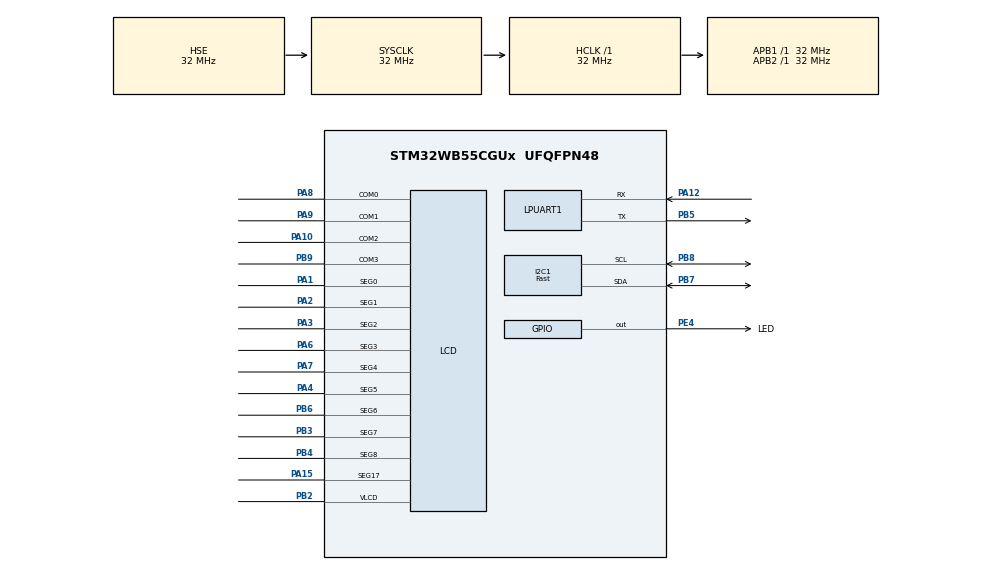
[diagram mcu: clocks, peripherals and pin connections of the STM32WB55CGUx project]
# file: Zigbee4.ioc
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Dma.LPUART1_RX.1.Direction=DMA_PERIPH_TO_MEMORY
Dma.LPUART1_RX.1.EventEnable=DISABLE
Dma.LPUART1_RX.1.Instance=DMA1_Channel2
Dma.LPUART1_RX.1.MemDataAlignment=DMA_MDATAALIGN_BYTE
Dma.LPUART1_RX.1.MemInc=DMA_MINC_ENABLE
Dma.LPUART1_RX.1.Mode=DMA_NORMAL
Dma.LPUART1_RX.1.PeriphDataAlignment=DMA_PDATAALIGN_BYTE
Dma.LPUART1_RX.1.PeriphInc=DMA_PINC_DISABLE
Dma.LPUART1_RX.1.Polarity=HAL_DMAMUX_REQ_GEN_RISING
Dma.LPUART1_RX.1.Priority=DMA_PRIORITY_LOW
Dma.LPUART1_RX.1.RequestNumber=1
Dma.LPUART1_RX.1.SignalID=NONE
Dma.LPUART1_RX.1.SyncEnable=DISABLE
Dma.LPUART1_RX.1.SyncPolarity=HAL_DMAMUX_SYNC_NO_EVENT
Dma.LPUART1_RX.1.SyncRequestNumber=1
Dma.LPUART1_RX.1.SyncSignalID=NONE
Dma.LPUART1_TX.0.Direction=DMA_MEMORY_TO_PERIPH
Dma.LPUART1_TX.0.EventEnable=DISABLE
Dma.LPUART1_TX.0.Instance=DMA1_Channel1
Dma.LPUART1_TX.0.MemDataAlignment=DMA_MDATAALIGN_BYTE
Dma.LPUART1_TX.0.MemInc=DMA_MINC_ENABLE
Dma.LPUART1_TX.0.Mode=DMA_NORMAL
Dma.LPUART1_TX.0.PeriphDataAlignment=DMA_PDATAALIGN_BYTE
Dma.LPUART1_TX.0.PeriphInc=DMA_PINC_DISABLE
Dma.LPUART1_TX.0.Polarity=HAL_DMAMUX_REQ_GEN_RISING
Dma.LPUART1_TX.0.Priority=DMA_PRIORITY_LOW
Dma.LPUART1_TX.0.RequestNumber=1
Dma.LPUART1_TX.0.SignalID=NONE
Dma.LPUART1_TX.0.SyncEnable=DISABLE
Dma.LPUART1_TX.0.SyncPolarity=HAL_DMAMUX_SYNC_NO_EVENT
Dma.LPUART1_TX.0.SyncRequestNumber=1
Dma.LPUART1_TX.0.SyncSignalID=NONE
Dma.Request0=LPUART1_TX
Dma.Request1=LPUART1_RX
I2C1.DualAddressMode=I2C_DUALADDRESS_ENABLE
I2C1.I2C_Speed_Mode=I2C_Fast
I2C1.Timing=0x0060112F
LCD.Bias=LCD_BIAS_1_3
LCD.BlinkFrequency=LCD_BLINKFREQUENCY_DIV8
LCD.BlinkMode=LCD_BLINKMODE_OFF
LCD.Contrast=LCD_CONTRASTLEVEL_3
LCD.HighDrive=LCD_HIGHDRIVE_ENABLE
Mcu.Family=STM32WB
Mcu.Name=STM32WB55CGUx
Mcu.Package=UFQFPN48
Mcu.UserConstants=TEMP_MIN_2,-4000;TEMP_MAX_2,14500;TEMP_TOLERANCE_2,10
NVIC.C2SEV_PWR_C2H_IRQn=true\:0\:0\:false\:false\:true\:true\:false\:true
NVIC.DMA1_Channel1_IRQn=true\:0\:0\:false\:false\:true\:false\:true\:true
NVIC.DMA1_Channel2_IRQn=true\:0\:0\:false\:false\:true\:false\:true\:true
NVIC.FLASH_IRQn=true\:0\:0\:false\:false\:true\:true\:true\:true
NVIC.FPU_IRQn=true\:0\:0\:false\:false\:true\:true\:false\:true
NVIC.HSEM_IRQn=true\:0\:0\:false\:false\:true\:false\:true\:true
NVIC.I2C1_EV_IRQn=true\:0\:0\:false\:false\:true\:true\:true\:true
NVIC.IPCC_C1_RX_IRQn=true\:0\:0\:false\:false\:true\:true\:true\:true
NVIC.IPCC_C1_TX_IRQn=true\:0\:0\:false\:false\:true\:true\:true\:true
NVIC.PVD_PVM_IRQn=true\:0\:0\:false\:false\:true\:true\:true\:true
NVIC.PWR_SOTF_BLEACT_802ACT_RFPHASE_IRQn=true\:0\:0\:false\:false\:true\:true\:false\:true
NVIC.PriorityGroup=NVIC_PRIORITYGROUP_4
NVIC.RTC_WKUP_IRQn=true\:0\:0\:false\:false\:true\:true\:true\:true
NVIC.TIM1_UP_TIM16_IRQn=true\:0\:0\:false\:false\:true\:true\:true\:true
OSC_IN.Mode=HSE-External-Oscillator
OSC_IN.Signal=RCC_OSC_IN
OSC_OUT.Mode=HSE-External-Oscillator
OSC_OUT.Signal=RCC_OSC_OUT
PA1.Mode=SEG0
PA1.Signal=LCD_SEG0
PA10.Mode=1/4 Duty Cycle
PA10.Signal=LCD_COM2
PA12.Mode=Asynchronous
PA12.Signal=LPUART1_RX
PA13.Mode=Serial_Wire
PA13.Signal=SYS_JTMS-SWDIO
PA14.Mode=Serial_Wire
PA14.Signal=SYS_JTCK-SWCLK
PA15.Mode=SEG17
PA15.Signal=LCD_SEG17
PA2.Mode=SEG1
PA2.Signal=LCD_SEG1
PA3.Mode=SEG2
PA3.Signal=LCD_SEG2
PA4.Mode=SEG5
PA4.Signal=LCD_SEG5
PA6.Mode=SEG3
PA6.Signal=LCD_SEG3
PA7.Mode=SEG4
PA7.Signal=LCD_SEG4
PA8.Mode=1/4 Duty Cycle
PA8.Signal=LCD_COM0
PA9.Mode=1/4 Duty Cycle
PA9.Signal=LCD_COM1
PB2.Mode=1/4 Duty Cycle
PB2.Signal=LCD_VLCD
PB3.Mode=SEG7
PB3.Signal=LCD_SEG7
PB4.Mode=SEG8
PB4.Signal=LCD_SEG8
PB5.Mode=Asynchronous
PB5.Signal=LPUART1_TX
PB6.Mode=SEG6
PB6.Signal=LCD_SEG6
PB7.Mode=I2C
PB7.Signal=I2C1_SDA
PB8.Mode=I2C
PB8.Signal=I2C1_SCL
PB9.Mode=1/4 Duty Cycle
PB9.Signal=LCD_COM3
PC14-OSC32_IN.Mode=LSE-External-Oscillator
PC14-OSC32_IN.Signal=RCC_OSC32_IN
PC15-OSC32_OUT.Mode=LSE-External-Oscillator
PC15-OSC32_OUT.Signal=RCC_OSC32_OUT
PE4.GPIO_Label=LED
PE4.Signal=GPIO_Output
ProjectManager.HeapSize=0x19000
ProjectManager.StackSize=0x1000
ProjectManager.TargetToolchain=CMake
RCC.AHBFreq_Value=32000000
RCC.APB1Freq_Value=32000000
RCC.APB1TimFreq_Value=32000000
RCC.APB2Freq_Value=32000000
RCC.APB2TimFreq_Value=32000000
RCC.APB3Freq_Value=16000000
RCC.CortexFreq_Value=32000000
RCC.HCLKFreq_Value=32000000
RCC.HSE_VALUE=32000000
RCC.HSI48_VALUE=48000000
RCC.HSI_VALUE=16000000
RCC.RTCClockSelection=RCC_RTCCLKSOURCE_LSE
RCC.SMPSCLockSelection=RCC_SMPSCLKSOURCE_HSE
RCC.SYSCLKFreq_VALUE=32000000
RCC.SYSCLKSource=RCC_SYSCLKSOURCE_HSE
RCC.VCOOutputFreq_Value=32000000
RF1.Mode=RF1_Activate
RF1.Signal=RF_RF1
STM32_WPAN.APPLI_CONFIG_LOG_LEVEL=LOG_LEVEL_DEBG
STM32_WPAN.CFG_CLI_UART=hw_lpuart1
STM32_WPAN.CFG_DEBUG_TRACE_FULL=1
STM32_WPAN.CFG_DEBUG_TRACE_LIGHT=1
STM32_WPAN.CFG_DEBUG_TRACE_UART=hw_uart1
STM32_WPAN.CFG_HW_LPUART1_ENABLED=1
STM32_WPAN.CFG_HW_USART1_ENABLED=1
STM32_WPAN.CFG_LSCLK_LSE=0
STM32_WPAN.CFG_USE_SMPS=1
STM32_WPAN.ENDPOINT1_DEVICE_ID=ZCL_DEVICE_METER_INTERFACE
STM32_WPAN.ENDPOINT1_ID_ZGB=10
STM32_WPAN.ENDPOINT2_DEVICE_ID=ZCL_DEVICE_METER_INTERFACE
STM32_WPAN.ENDPOINT2_ID_ZGB=11
STM32_WPAN.ZCL_BASIC_ENDPOINT1=CLIENT_SERVER
STM32_WPAN.ZCL_BASIC_ENDPOINT2=CLIENT_SERVER
STM32_WPAN.ZCL_IDENTIFY_ENDPOINT1=NONE
STM32_WPAN.ZCL_TEMPERATURE_MEASUREMENT_ENDPOINT2=CLIENT_SERVER
STM32_WPAN.ZCL_WATER_CONTENT_MEASUREMENT_ENDPOINT1=CLIENT_SERVER
STM32_WPAN.ZGB_CHANNEL=13
STM32_WPAN.ZGB_DEVICE_ROLE=ROUTER
STM32_WPAN.ZGB_ENDPOINT1_PROFILE_ID=ZCL_PROFILE_HOME_AUTOMATION
STM32_WPAN.ZGB_NB_ENDPOINTS=3
STM32_WPAN.ZGB_NW_MODE=CENTRALIZED
TIM1.Period=50000
TIM1.Prescaler=720
VP_HSEM_VS_HSEM.Mode=HSEM_Activate
VP_IPCC_VS_IPCC.Mode=IPCC_Activate
VP_MEMORYMAP_VS_MEMORYMAP.Mode=CurAppReg
VP_RTC_VS_RTC_Activate.Mode=RTC_Enabled
VP_RTC_VS_RTC_WakeUp_intern.Mode=WakeUp
VP_SEQUENCER_VS_SEQUENCER.Mode=SEQUENCER_Enabled
VP_STM32_WPAN_VS_ZIGBEE.Mode=MOD_ZGB_ENDPOINT
VP_TIM1_VS_ClockSourceINT.Mode=Internal
VP_TINY_LPM_VS_TINY_LPM.Mode=TINY_LPM_Enabled
board=custom

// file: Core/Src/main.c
/* USER CODE BEGIN Header */
/**
  ******************************************************************************
  * @file           : main.c
  * @brief          : Main program body
  ******************************************************************************
  * @attention
  *
  * Copyright (c) 2025 STMicroelectronics.
  * All rights reserved.
  *
  * This software is licensed under terms that can be found in the LICENSE file
  * in the root directory of this software component.
  * If no LICENSE file comes with this software, it is provided AS-IS.
  *
  ******************************************************************************
  */
/* USER CODE END Header */
#include "main.h"

I2C_HandleTypeDef hi2c1;

IPCC_HandleTypeDef hipcc;

LCD_HandleTypeDef hlcd;

UART_HandleTypeDef hlpuart1;
DMA_HandleTypeDef hdma_lpuart1_tx;
DMA_HandleTypeDef hdma_lpuart1_rx;

RTC_HandleTypeDef hrtc;

TIM_HandleTypeDef htim1;

void SystemClock_Config(void);
void PeriphCommonClock_Config(void);
static void MX_GPIO_Init(void);
static void MX_DMA_Init(void);
static void MX_LPUART1_UART_Init(void);
static void MX_IPCC_Init(void);
static void MX_RTC_Init(void);
static void MX_I2C1_Init(void);
static void MX_TIM1_Init(void);
static void MX_LCD_Init(void);
static void MX_RF_Init(void);
/* USER CODE BEGIN PFP */

extern void TimerCallBack();

/* USER CODE END PFP */

/* USER CODE BEGIN 0 */
void HAL_TIM_PeriodElapsedCallback(TIM_HandleTypeDef *htim)
{
        if(htim->Instance == TIM1) //check if the interrupt comes from TIM1
        {
          TimerCallBack();
        }
}
/* USER CODE END 0 */

int main(void)
{

  /* MCU Configuration--------------------------------------------------------*/

  /* Reset of all peripherals, Initializes the Flash interface and the Systick. */
  HAL_Init();
  /* Config code for STM32_WPAN (HSE Tuning must be done before system clock configuration) */
  MX_APPE_Config();

  /* Configure the system clock */
  SystemClock_Config();

  /* Configure the peripherals common clocks */
  PeriphCommonClock_Config();

  /* IPCC initialisation */
  MX_IPCC_Init();

  /* Initialize all configured peripherals */
  MX_GPIO_Init();
  MX_DMA_Init();
  MX_LPUART1_UART_Init();
  MX_RTC_Init();
  MX_I2C1_Init();
  MX_TIM1_Init();
  MX_LCD_Init();
  MX_RF_Init();
  /* USER CODE BEGIN 2 */
  HAL_TIM_Base_Start_IT(&htim1);

  /* USER CODE END 2 */

  /* Init code for STM32_WPAN */
  MX_APPE_Init();

  /* Infinite loop */
  while (1)
  {
    MX_APPE_Process();

  }
}

void SystemClock_Config(void)
{
  RCC_OscInitTypeDef RCC_OscInitStruct = {0};
  RCC_ClkInitTypeDef RCC_ClkInitStruct = {0};

  /** Configure LSE Drive Capability
  */
  HAL_PWR_EnableBkUpAccess();
  __HAL_RCC_LSEDRIVE_CONFIG(RCC_LSEDRIVE_MEDIUMHIGH);

  /** Configure the main internal regulator output voltage
  */
  __HAL_PWR_VOLTAGESCALING_CONFIG(PWR_REGULATOR_VOLTAGE_SCALE1);

  /** Initializes the RCC Oscillators according to the specified parameters
  * in the RCC_OscInitTypeDef structure.
  */
  RCC_OscInitStruct.OscillatorType = RCC_OSCILLATORTYPE_HSI|RCC_OSCILLATORTYPE_HSE
                              |RCC_OSCILLATORTYPE_LSE;
  RCC_OscInitStruct.HSEState = RCC_HSE_ON;
  RCC_OscInitStruct.LSEState = RCC_LSE_ON;
  RCC_OscInitStruct.HSIState = RCC_HSI_ON;
  RCC_OscInitStruct.HSICalibrationValue = RCC_HSICALIBRATION_DEFAULT;
  RCC_OscInitStruct.PLL.PLLState = RCC_PLL_NONE;
  if (HAL_RCC_OscConfig(&RCC_OscInitStruct) != HAL_OK)
  {
    Error_Handler();
  }

  /** Configure the SYSCLKSource, HCLK, PCLK1 and PCLK2 clocks dividers
  */
  RCC_ClkInitStruct.ClockType = RCC_CLOCKTYPE_HCLK4|RCC_CLOCKTYPE_HCLK2
                              |RCC_CLOCKTYPE_HCLK|RCC_CLOCKTYPE_SYSCLK
                              |RCC_CLOCKTYPE_PCLK1|RCC_CLOCKTYPE_PCLK2;
  RCC_ClkInitStruct.SYSCLKSource = RCC_SYSCLKSOURCE_HSE;
  RCC_ClkInitStruct.AHBCLKDivider = RCC_SYSCLK_DIV1;
  RCC_ClkInitStruct.APB1CLKDivider = RCC_HCLK_DIV1;
  RCC_ClkInitStruct.APB2CLKDivider = RCC_HCLK_DIV1;
  RCC_ClkInitStruct.AHBCLK2Divider = RCC_SYSCLK_DIV1;
  RCC_ClkInitStruct.AHBCLK4Divider = RCC_SYSCLK_DIV1;

  if (HAL_RCC_ClockConfig(&RCC_ClkInitStruct, FLASH_LATENCY_1) != HAL_OK)
  {
    Error_Handler();
  }
}

void PeriphCommonClock_Config(void)
{
  RCC_PeriphCLKInitTypeDef PeriphClkInitStruct = {0};

  /** Initializes the peripherals clock
  */
  PeriphClkInitStruct.PeriphClockSelection = RCC_PERIPHCLK_SMPS|RCC_PERIPHCLK_RFWAKEUP;
  PeriphClkInitStruct.RFWakeUpClockSelection = RCC_RFWKPCLKSOURCE_HSE_DIV1024;
  PeriphClkInitStruct.SmpsClockSelection = RCC_SMPSCLKSOURCE_HSE;
  PeriphClkInitStruct.SmpsDivSelection = RCC_SMPSCLKDIV_RANGE0;

  if (HAL_RCCEx_PeriphCLKConfig(&PeriphClkInitStruct) != HAL_OK)
  {
    Error_Handler();
  }
}

static void MX_I2C1_Init(void)
{

  hi2c1.Instance = I2C1;
  hi2c1.Init.Timing = 0x0060112F;
  hi2c1.Init.OwnAddress1 = 0;
  hi2c1.Init.AddressingMode = I2C_ADDRESSINGMODE_7BIT;
  hi2c1.Init.DualAddressMode = I2C_DUALADDRESS_ENABLE;
  hi2c1.Init.OwnAddress2 = 0;
  hi2c1.Init.OwnAddress2Masks = I2C_OA2_NOMASK;
  hi2c1.Init.GeneralCallMode = I2C_GENERALCALL_DISABLE;
  hi2c1.Init.NoStretchMode = I2C_NOSTRETCH_DISABLE;
  if (HAL_I2C_Init(&hi2c1) != HAL_OK)
  {
    Error_Handler();
  }

  /** Configure Analogue filter
  */
  if (HAL_I2CEx_ConfigAnalogFilter(&hi2c1, I2C_ANALOGFILTER_ENABLE) != HAL_OK)
  {
    Error_Handler();
  }

  /** Configure Digital filter
  */
  if (HAL_I2CEx_ConfigDigitalFilter(&hi2c1, 0) != HAL_OK)
  {
    Error_Handler();
  }

}

static void MX_IPCC_Init(void)
{

  hipcc.Instance = IPCC;
  if (HAL_IPCC_Init(&hipcc) != HAL_OK)
  {
    Error_Handler();
  }

}

static void MX_LCD_Init(void)
{

  hlcd.Instance = LCD;
  hlcd.Init.Prescaler = LCD_PRESCALER_1;
  hlcd.Init.Divider = LCD_DIVIDER_16;
  hlcd.Init.Duty = LCD_DUTY_1_4;
  hlcd.Init.Bias = LCD_BIAS_1_3;
  hlcd.Init.VoltageSource = LCD_VOLTAGESOURCE_INTERNAL;
  hlcd.Init.Contrast = LCD_CONTRASTLEVEL_3;
  hlcd.Init.DeadTime = LCD_DEADTIME_0;
  hlcd.Init.PulseOnDuration = LCD_PULSEONDURATION_1;
  hlcd.Init.MuxSegment = LCD_MUXSEGMENT_DISABLE;
  hlcd.Init.BlinkMode = LCD_BLINKMODE_OFF;
  hlcd.Init.BlinkFrequency = LCD_BLINKFREQUENCY_DIV8;
  hlcd.Init.HighDrive = LCD_HIGHDRIVE_ENABLE;
  if (HAL_LCD_Init(&hlcd) != HAL_OK)
  {
    Error_Handler();
  }

  /** Enable the High Driver
  */
  __HAL_LCD_HIGHDRIVER_ENABLE(&hlcd);

}

static void MX_LPUART1_UART_Init(void)
{

  hlpuart1.Instance = LPUART1;
  hlpuart1.Init.BaudRate = 115200;
  hlpuart1.Init.WordLength = UART_WORDLENGTH_8B;
  hlpuart1.Init.StopBits = UART_STOPBITS_1;
  hlpuart1.Init.Parity = UART_PARITY_NONE;
  hlpuart1.Init.Mode = UART_MODE_TX_RX;
  hlpuart1.Init.HwFlowCtl = UART_HWCONTROL_NONE;
  hlpuart1.Init.OneBitSampling = UART_ONE_BIT_SAMPLE_DISABLE;
  hlpuart1.Init.ClockPrescaler = UART_PRESCALER_DIV1;
  hlpuart1.AdvancedInit.AdvFeatureInit = UART_ADVFEATURE_NO_INIT;
  hlpuart1.FifoMode = UART_FIFOMODE_DISABLE;
  if (HAL_UART_Init(&hlpuart1) != HAL_OK)
  {
    Error_Handler();
  }
  if (HAL_UARTEx_SetTxFifoThreshold(&hlpuart1, UART_TXFIFO_THRESHOLD_1_8) != HAL_OK)
  {
    Error_Handler();
  }
  if (HAL_UARTEx_SetRxFifoThreshold(&hlpuart1, UART_RXFIFO_THRESHOLD_1_8) != HAL_OK)
  {
    Error_Handler();
  }
  if (HAL_UARTEx_DisableFifoMode(&hlpuart1) != HAL_OK)
  {
    Error_Handler();
  }

}

static void MX_RF_Init(void)
{

}

static void MX_RTC_Init(void)
{

  /** Initialize RTC Only
  */
  hrtc.Instance = RTC;
  hrtc.Init.HourFormat = RTC_HOURFORMAT_24;
  hrtc.Init.AsynchPrediv = CFG_RTC_ASYNCH_PRESCALER;
  hrtc.Init.SynchPrediv = CFG_RTC_SYNCH_PRESCALER;
  hrtc.Init.OutPut = RTC_OUTPUT_DISABLE;
  hrtc.Init.OutPutPolarity = RTC_OUTPUT_POLARITY_HIGH;
  hrtc.Init.OutPutType = RTC_OUTPUT_TYPE_OPENDRAIN;
  hrtc.Init.OutPutRemap = RTC_OUTPUT_REMAP_NONE;
  if (HAL_RTC_Init(&hrtc) != HAL_OK)
  {
    Error_Handler();
  }

  /** Enable the WakeUp
  */
  if (HAL_RTCEx_SetWakeUpTimer_IT(&hrtc, 0, RTC_WAKEUPCLOCK_RTCCLK_DIV16) != HAL_OK)
  {
    Error_Handler();
  }

}

static void MX_TIM1_Init(void)
{

  TIM_ClockConfigTypeDef sClockSourceConfig = {0};
  TIM_MasterConfigTypeDef sMasterConfig = {0};

  htim1.Instance = TIM1;
  htim1.Init.Prescaler = 720;
  htim1.Init.CounterMode = TIM_COUNTERMODE_UP;
  htim1.Init.Period = 50000;
  htim1.Init.ClockDivision = TIM_CLOCKDIVISION_DIV1;
  htim1.Init.RepetitionCounter = 0;
  htim1.Init.AutoReloadPreload = TIM_AUTORELOAD_PRELOAD_DISABLE;
  if (HAL_TIM_Base_Init(&htim1) != HAL_OK)
  {
    Error_Handler();
  }
  sClockSourceConfig.ClockSource = TIM_CLOCKSOURCE_INTERNAL;
  if (HAL_TIM_ConfigClockSource(&htim1, &sClockSourceConfig) != HAL_OK)
  {
    Error_Handler();
  }
  sMasterConfig.MasterOutputTrigger = TIM_TRGO_RESET;
  sMasterConfig.MasterOutputTrigger2 = TIM_TRGO2_RESET;
  sMasterConfig.MasterSlaveMode = TIM_MASTERSLAVEMODE_DISABLE;
  if (HAL_TIMEx_MasterConfigSynchronization(&htim1, &sMasterConfig) != HAL_OK)
  {
    Error_Handler();
  }

}

static void MX_DMA_Init(void)
{

  /* DMA controller clock enable */
  __HAL_RCC_DMAMUX1_CLK_ENABLE();
  __HAL_RCC_DMA1_CLK_ENABLE();

  /* DMA interrupt init */
  /* DMA1_Channel1_IRQn interrupt configuration */
  HAL_NVIC_SetPriority(DMA1_Channel1_IRQn, 0, 0);
  HAL_NVIC_EnableIRQ(DMA1_Channel1_IRQn);
  /* DMA1_Channel2_IRQn interrupt configuration */
  HAL_NVIC_SetPriority(DMA1_Channel2_IRQn, 0, 0);
  HAL_NVIC_EnableIRQ(DMA1_Channel2_IRQn);

}

static void MX_GPIO_Init(void)
{
  GPIO_InitTypeDef GPIO_InitStruct = {0};

  /* GPIO Ports Clock Enable */
  __HAL_RCC_GPIOC_CLK_ENABLE();
  __HAL_RCC_GPIOB_CLK_ENABLE();
  __HAL_RCC_GPIOA_CLK_ENABLE();
  __HAL_RCC_GPIOE_CLK_ENABLE();

  /*Configure GPIO pin Output Level */
  HAL_GPIO_WritePin(LED_GPIO_Port, LED_Pin, GPIO_PIN_RESET);

  /*Configure GPIO pin : LED_Pin */
  GPIO_InitStruct.Pin = LED_Pin;
  GPIO_InitStruct.Mode = GPIO_MODE_OUTPUT_PP;
  GPIO_InitStruct.Pull = GPIO_NOPULL;
  GPIO_InitStruct.Speed = GPIO_SPEED_FREQ_LOW;
  HAL_GPIO_Init(LED_GPIO_Port, &GPIO_InitStruct);

}

void Error_Handler(void)
{
  __disable_irq();
  while (1)
  {
  }
}
